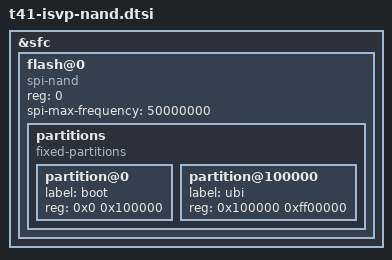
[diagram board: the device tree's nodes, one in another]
// SPDX-License-Identifier: GPL-2.0+
/*
 * Ingenic ISVP-T41 SFC-NAND boot-media fragment: re-declare the SFC
 * flash@0 node as SPI-NAND (the shared t41-isvp.dtsi declares it as
 * jedec,spi-nor for the NOR SKUs) and add the partition map. Included
 * by NAND-boot leaf .dts files after t41-isvp.dtsi.
 */

&sfc {
	flash@0 {
		compatible = "spi-nand";
		reg = <0>;
		spi-max-frequency = <50000000>;

		partitions {
			compatible = "fixed-partitions";
			#address-cells = <1>;
			#size-cells = <1>;

			/*
			 * Layout (SPI-NAND, 128 KiB erase block):
			 *   boot 1 MiB : raw SPL @ 0 + raw U-Boot @ 0x80000
			 *                (matches binman u-boot-with-spl-lzma.bin;
			 *                the SPL reads U-Boot from T41_NAND_UBOOT_OFFSET)
			 *   ubi  rest  : UBI container - holds uboot-env, kernel
			 *                (FIT), rootfs (squashfs) and overlay (UBIFS)
			 *                as named volumes.
			 * The U-Boot env lives in the UBI volume "uboot-env"
			 * (CONFIG_ENV_IS_IN_UBI) so it survives bad blocks via UBI
			 * wear-leveling.
			 *
			 * The "ubi" size below assumes a 256 MiB SPI-NAND; adjust
			 * it to the board's actual chip (thingino also overrides the
			 * runtime mtdparts via its sfc0_nand layout).
			 */
			partition@0 {
				label = "boot";
				reg = <0x0 0x100000>;
			};

			partition@100000 {
				label = "ubi";
				reg = <0x100000 0xff00000>;
			};
		};
	};
};
